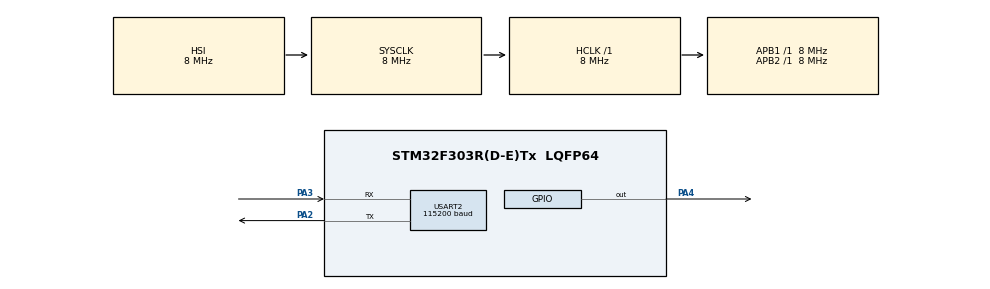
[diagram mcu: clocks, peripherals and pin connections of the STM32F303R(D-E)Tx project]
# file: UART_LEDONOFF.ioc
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Mcu.Family=STM32F3
RCC.CortexFreq_Value=8000000
NVIC.USART2_IRQn=true\:0\:0\:false\:false\:true\:true\:true
USART2.BaudRate=115200
ProjectManager.StackSize=0x400
PA13.Signal=SYS_JTMS-SWDIO
PA3.Mode=Asynchronous
ProjectManager.TargetToolchain=STM32CubeIDE
RCC.USBFreq_Value=16000000
RCC.LSE_VALUE=32768
RCC.AHBFreq_Value=8000000
RCC.HSE_VALUE=8000000
board=custom
USART2.VirtualMode-Asynchronous=VM_ASYNC
RCC.APB2Freq_Value=8000000
PA14.Mode=Serial_Wire
PA13.Mode=Serial_Wire
Mcu.Name=STM32F303R(D-E)Tx
PA2.Signal=USART2_TX
RCC.SYSCLKFreq_VALUE=8000000
PA4.Signal=GPIO_Output
Mcu.Package=LQFP64
PA14.Signal=SYS_JTCK-SWCLK
ProjectManager.HeapSize=0x200
RCC.HSI_VALUE=8000000
NVIC.PriorityGroup=NVIC_PRIORITYGROUP_4
PA2.Mode=Asynchronous
RCC.APB1Freq_Value=8000000
PA3.Signal=USART2_RX

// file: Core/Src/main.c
/* USER CODE BEGIN Header */
/**
  ******************************************************************************
  * @file           : main.c
  * @brief          : Main program body
  ******************************************************************************
  * @attention
  *
  * <h2><center>&copy; Copyright (c) 2021 STMicroelectronics.
  * All rights reserved.</center></h2>
  *
  * This software component is licensed by ST under BSD 3-Clause license,
  * the "License"; You may not use this file except in compliance with the
  * License. You may obtain a copy of the License at:
  *                        opensource.org/licenses/BSD-3-Clause
  *
  ******************************************************************************
  */
/* USER CODE END Header */
#include "main.h"

/* USER CODE BEGIN Includes */
#include "string.h"
/* USER CODE END Includes */

UART_HandleTypeDef huart2;

/* USER CODE BEGIN PV */
char Rx_byte[2] = {0}; //Nhan mot byte ky tu den
char Rx_buffer[10] = {0}; //Tong hop cac byte da nhan
uint8_t Rx_count = 0; //Chi so mang - So byte da nhan
uint32_t Rx_time = 0; //Thoi gian tai thoi diem nhan mot byte
/* USER CODE END PV */

void SystemClock_Config(void);
static void MX_GPIO_Init(void);
static void MX_USART2_UART_Init(void);

/* USER CODE BEGIN 0 */
void HAL_UART_RxCpltCallback(UART_HandleTypeDef *huart)
{
	if((HAL_GetTick() - Rx_time > 1000) | (Rx_count > 10)) //Neu thoi gian nhan giua 2 byte lien tiep > 1s hoac
										   //Neu nhan duoc so byte lon hon so voi kich thuoc da khai bao
	{
		for(uint8_t i = 0; i < 10; i++) //Xoa mang sau khi xu ly du lieu
		{
			Rx_buffer[i] = 0;
		}
		Rx_count = 0; //Dua chi so mang ve lai 0 de tranh tran bo dem
	}
	Rx_buffer[Rx_count++] = Rx_byte[0];
	if(Rx_byte[0] == '\n') //Neu da nhan du chuoi
	{
		if(strstr(Rx_buffer,"LEDON\n") != NULL) //Neu co xuat hien "LEDON\n"
		{
			HAL_GPIO_WritePin(GPIOA, GPIO_PIN_5, GPIO_PIN_SET); //Bat LED
		}
		else if(strstr(Rx_buffer,"LEDOFF\n") != NULL) //Neu co xuat hien "LEDOFF\n"
		{
			HAL_GPIO_WritePin(GPIOA, GPIO_PIN_5, GPIO_PIN_RESET); //Tat LED
		}
	}
	Rx_time = HAL_GetTick();
	HAL_UART_Receive_IT(huart, (uint8_t *)Rx_byte, 1); //Doi du lieu den
}
/* USER CODE END 0 */

int main(void)
{

  /* MCU Configuration--------------------------------------------------------*/

  /* Reset of all peripherals, Initializes the Flash interface and the Systick. */
  HAL_Init();

  /* Configure the system clock */
  SystemClock_Config();

  /* Initialize all configured peripherals */
  MX_GPIO_Init();
  MX_USART2_UART_Init();
  /* USER CODE BEGIN 2 */
  HAL_UART_Receive_IT(&huart2, (uint8_t *)Rx_byte, 1); //Doi du lieu den
  Rx_time = HAL_GetTick();

  /* USER CODE END 2 */

  /* Infinite loop */
  while (1)
  {

  }
}

void SystemClock_Config(void)
{
  RCC_OscInitTypeDef RCC_OscInitStruct = {0};
  RCC_ClkInitTypeDef RCC_ClkInitStruct = {0};
  RCC_PeriphCLKInitTypeDef PeriphClkInit = {0};

  /** Initializes the RCC Oscillators according to the specified parameters
  * in the RCC_OscInitTypeDef structure.
  */
  RCC_OscInitStruct.OscillatorType = RCC_OSCILLATORTYPE_HSI;
  RCC_OscInitStruct.HSIState = RCC_HSI_ON;
  RCC_OscInitStruct.HSICalibrationValue = RCC_HSICALIBRATION_DEFAULT;
  RCC_OscInitStruct.PLL.PLLState = RCC_PLL_NONE;
  if (HAL_RCC_OscConfig(&RCC_OscInitStruct) != HAL_OK)
  {
    Error_Handler();
  }
  /** Initializes the CPU, AHB and APB buses clocks
  */
  RCC_ClkInitStruct.ClockType = RCC_CLOCKTYPE_HCLK|RCC_CLOCKTYPE_SYSCLK
                              |RCC_CLOCKTYPE_PCLK1|RCC_CLOCKTYPE_PCLK2;
  RCC_ClkInitStruct.SYSCLKSource = RCC_SYSCLKSOURCE_HSI;
  RCC_ClkInitStruct.AHBCLKDivider = RCC_SYSCLK_DIV1;
  RCC_ClkInitStruct.APB1CLKDivider = RCC_HCLK_DIV1;
  RCC_ClkInitStruct.APB2CLKDivider = RCC_HCLK_DIV1;

  if (HAL_RCC_ClockConfig(&RCC_ClkInitStruct, FLASH_LATENCY_0) != HAL_OK)
  {
    Error_Handler();
  }
  PeriphClkInit.PeriphClockSelection = RCC_PERIPHCLK_USART2;
  PeriphClkInit.Usart2ClockSelection = RCC_USART2CLKSOURCE_PCLK1;
  if (HAL_RCCEx_PeriphCLKConfig(&PeriphClkInit) != HAL_OK)
  {
    Error_Handler();
  }
}

static void MX_USART2_UART_Init(void)
{

  huart2.Instance = USART2;
  huart2.Init.BaudRate = 115200;
  huart2.Init.WordLength = UART_WORDLENGTH_8B;
  huart2.Init.StopBits = UART_STOPBITS_1;
  huart2.Init.Parity = UART_PARITY_NONE;
  huart2.Init.Mode = UART_MODE_TX_RX;
  huart2.Init.HwFlowCtl = UART_HWCONTROL_NONE;
  huart2.Init.OverSampling = UART_OVERSAMPLING_16;
  huart2.Init.OneBitSampling = UART_ONE_BIT_SAMPLE_DISABLE;
  huart2.AdvancedInit.AdvFeatureInit = UART_ADVFEATURE_NO_INIT;
  if (HAL_UART_Init(&huart2) != HAL_OK)
  {
    Error_Handler();
  }

}

static void MX_GPIO_Init(void)
{
  GPIO_InitTypeDef GPIO_InitStruct = {0};

  /* GPIO Ports Clock Enable */
  __HAL_RCC_GPIOA_CLK_ENABLE();

  /*Configure GPIO pin Output Level */
  HAL_GPIO_WritePin(GPIOA, GPIO_PIN_4, GPIO_PIN_RESET);

  /*Configure GPIO pin : PA4 */
  GPIO_InitStruct.Pin = GPIO_PIN_4;
  GPIO_InitStruct.Mode = GPIO_MODE_OUTPUT_PP;
  GPIO_InitStruct.Pull = GPIO_NOPULL;
  GPIO_InitStruct.Speed = GPIO_SPEED_FREQ_LOW;
  HAL_GPIO_Init(GPIOA, &GPIO_InitStruct);

}

void Error_Handler(void)
{
  __disable_irq();
  while (1)
  {
  }
}

/************************ (C) COPYRIGHT STMicroelectronics *****END OF FILE****/
